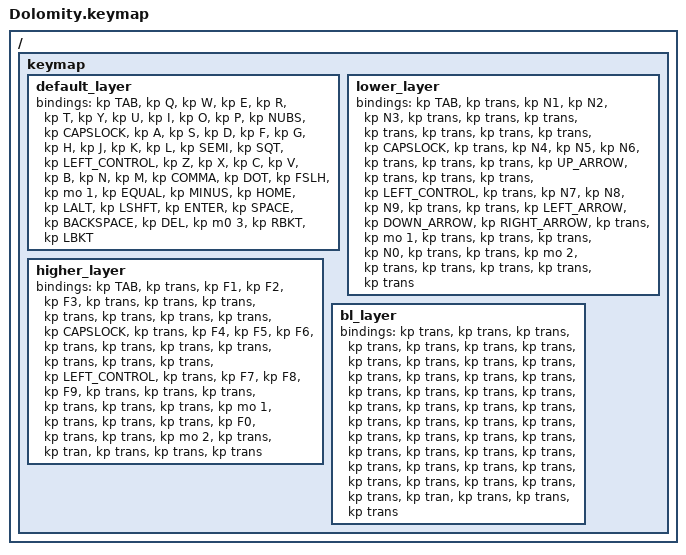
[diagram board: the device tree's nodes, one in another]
#include <behaviors.dtsi>
#include <dt-bindings/zmk/keys.h>
#include <bt-bindings/bt.h>

/ {
    keymap {
        default_layer {
        bindings = < 
        &kp TAB           &kp Q       &kp W       &kp E       &kp R     &kp T                                              &kp Y      &kp U    &kp I       &kp O      &kp P     &kp NUBS
        &kp CAPSLOCK      &kp A       &kp S       &kp D       &kp F     &kp G                                              &kp H      &kp J    &kp K       &kp L      &kp SEMI  &kp SQT
        &kp LEFT_CONTROL  &kp Z       &kp X       &kp C       &kp V     &kp B                                              &kp N      &kp M    &kp COMMA   &kp DOT    &kp FSLH  &kp mo 1
        &kp EQUAL         &kp MINUS   &kp HOME    &kp LALT              &kp LSHFT   &kp ENTER                  &kp SPACE   &kp BACKSPACE       &kp DEL     &kp m0 3   &kp RBKT  &kp LBKT
            >;
    };
        lower_layer {
        bindings = < 
        &kp TAB           &kp trans   &kp N1       &kp N2    &kp N3     &kp trans                                          &kp trans   &kp trans       &kp trans       &kp trans        &kp trans   &kp trans
        &kp CAPSLOCK      &kp trans   &kp N4       &kp N5    &kp N6     &kp trans                                          &kp trans   &kp trans       &kp UP_ARROW    &kp trans        &kp trans   &kp trans
        &kp LEFT_CONTROL  &kp trans   &kp N7       &kp N8    &kp N9     &kp trans                                          &kp trans   &kp LEFT_ARROW  &kp DOWN_ARROW  &kp RIGHT_ARROW  &kp trans   &kp mo 1
        &kp trans         &kp trans   &kp trans    &kp N0               &kp trans    &kp trans                 &kp mo 2    &kp trans       &kp trans       &kp trans        &kp trans   &kp trans
            >;
    };

        higher_layer {
        bindings = < 
        &kp TAB           &kp trans   &kp F1       &kp F2    &kp F3       &kp trans                                        &kp trans  &kp trans    &kp trans   &kp trans    &kp trans  &kp trans
        &kp CAPSLOCK      &kp trans   &kp F4       &kp F5    &kp F6       &kp trans                                        &kp trans  &kp trans    &kp trans   &kp trans    &kp trans  &kp trans
        &kp LEFT_CONTROL  &kp trans   &kp F7       &kp F8    &kp F9       &kp trans                                        &kp trans  &kp trans    &kp trans   &kp trans    &kp trans  &kp mo 1
        &kp trans         &kp trans   &kp trans    &kp F0                 &kp trans    &kp trans               &kp mo 2    &kp trans    &kp tran    &kp trans    &kp trans  &kp trans
            >;
    };

        bl_layer {
        bindings = < 
        &kp trans         &kp trans   &kp trans    &kp trans    &kp trans    &kp trans                   &kp trans  &kp trans    &kp trans   &kp trans    &kp trans  &kp trans
        &kp trans         &kp trans   &kp trans    &kp trans    &kp trans    &kp trans                   &kp trans  &kp trans    &kp trans   &kp trans    &kp trans  &kp trans
        &kp trans         &kp trans   &kp trans    &kp trans    &kp trans    &kp trans                   &kp trans  &kp trans    &kp trans   &kp trans    &kp trans  &kp trans
        &kp trans         &kp trans   &kp trans    &kp trans    &kp trans    &kp trans                   &kp trans  &kp trans    &kp tran    &kp trans    &kp trans  &kp trans
            >;
    };

    }
}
